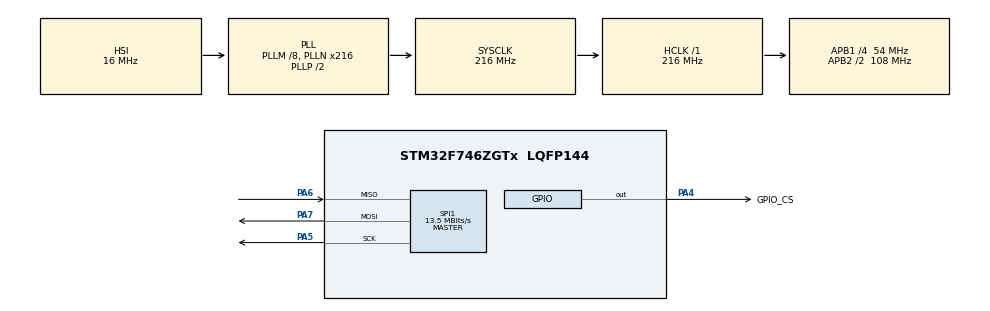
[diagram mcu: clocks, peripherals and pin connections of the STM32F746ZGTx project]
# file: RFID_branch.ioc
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Mcu.Family=STM32F7
Mcu.Name=STM32F746ZGTx
Mcu.Package=LQFP144
NVIC.PriorityGroup=NVIC_PRIORITYGROUP_4
PA4.GPIO_Label=GPIO_CS
PA4.Signal=GPIO_Output
PA5.Mode=Full_Duplex_Master
PA5.Signal=SPI1_SCK
PA6.Mode=Full_Duplex_Master
PA6.Signal=SPI1_MISO
PA7.Mode=Full_Duplex_Master
PA7.Signal=SPI1_MOSI
PH0/OSC_IN.Mode=HSE-External-Oscillator
PH0/OSC_IN.Signal=RCC_OSC_IN
PH1/OSC_OUT.Mode=HSE-External-Oscillator
PH1/OSC_OUT.Signal=RCC_OSC_OUT
ProjectManager.HeapSize=0x200
ProjectManager.StackSize=0x400
ProjectManager.TargetToolchain=STM32CubeIDE
RCC.AHBFreq_Value=216000000
RCC.APB1CLKDivider=RCC_HCLK_DIV4
RCC.APB1Freq_Value=54000000
RCC.APB1TimFreq_Value=108000000
RCC.APB2CLKDivider=RCC_HCLK_DIV2
RCC.APB2Freq_Value=108000000
RCC.APB2TimFreq_Value=216000000
RCC.CortexFreq_Value=216000000
RCC.HCLKFreq_Value=216000000
RCC.HSE_VALUE=25000000
RCC.HSI_VALUE=16000000
RCC.LSE_VALUE=32768
RCC.PLLM=8
RCC.PLLN=216
RCC.SYSCLKFreq_VALUE=216000000
RCC.SYSCLKSource=RCC_SYSCLKSOURCE_PLLCLK
RCC.USBFreq_Value=216000000
RCC.VCOOutputFreq_Value=432000000
SPI1.BaudRatePrescaler=SPI_BAUDRATEPRESCALER_8
SPI1.CalculateBaudRate=13.5 MBits/s
SPI1.DataSize=SPI_DATASIZE_8BIT
SPI1.Direction=SPI_DIRECTION_2LINES
SPI1.Mode=SPI_MODE_MASTER
SPI1.VirtualType=VM_MASTER
board=custom

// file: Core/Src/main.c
/* USER CODE BEGIN Header */
/**
  ******************************************************************************
  * @file           : main.c
  * @brief          : Main program body
  ******************************************************************************
  * @attention
  *
  * <h2><center>&copy; Copyright (c) 2021 STMicroelectronics.
  * All rights reserved.</center></h2>
  *
  * This software component is licensed by ST under BSD 3-Clause license,
  * the "License"; You may not use this file except in compliance with the
  * License. You may obtain a copy of the License at:
  *                        opensource.org/licenses/BSD-3-Clause
  *
  ******************************************************************************
  */
/* USER CODE END Header */
#include "main.h"

/* USER CODE BEGIN Includes */

#include "rfid-rc522.h"

/* USER CODE END Includes */

void SystemClock_Config(void);
static void MX_GPIO_Init(void);
static void MX_SPI1_Init(void);

int main(void)
{
  /* USER CODE BEGIN 1 */

  // TODO: set chip select high!
  HAL_GPIO_WritePin(GPIOA, GPIO_PIN_4, GPIO_PIN_RESET);

  /* Recognized card ID */
  uint8_t CardID[4];
  uint8_t type;
  char *result;
  uint8_t my_int_x;

  /* USER CODE END 1 */

  /* MCU Configuration--------------------------------------------------------*/

  /* Reset of all peripherals, Initializes the Flash interface and the Systick. */
  HAL_Init();

  /* Configure the system clock */
  SystemClock_Config();

  /* Initialize all configured peripherals */
  MX_GPIO_Init();
  MX_SPI1_Init();
  /* USER CODE BEGIN 2 */

  RFID_RC522_Init();

  /* USER CODE END 2 */

  /* Infinite loop */
  while (1)
  {

    /* USER CODE BEGIN 3 */

    int status = TM_MFRC522_Check(CardID, &type);
  	if (status == MI_OK) {
      my_int_x = my_int_x + 1;
      // LCD_UsrLog ((char *)"Found tag: ");
      // bin_to_strhex((unsigned char *)CardID, sizeof(CardID), &result);
      // LCD_UsrLog ((char *)result);
      // LCD_UsrLog ((char *)"\n");
      // LCD_UsrLog ((char *)"Type is: ");
      // bin_to_strhex((unsigned char *)&type, 1, &result);
      // LCD_UsrLog ((char *)result);
      // LCD_UsrLog ((char *)"\n");

  	} else {
        if (status == MI_TIMEOUT) {
            // LCD_UsrLog ((char *)"No tag found.\n");
        }
        if (status == MI_ERR) {
            // LCD_UsrLog ((char *)"Error.\n");
        }
    }

  }
  /* USER CODE END 3 */
}

void SystemClock_Config(void)
{
  RCC_OscInitTypeDef RCC_OscInitStruct = {0};
  RCC_ClkInitTypeDef RCC_ClkInitStruct = {0};

  /** Configure the main internal regulator output voltage
  */
  __HAL_RCC_PWR_CLK_ENABLE();
  __HAL_PWR_VOLTAGESCALING_CONFIG(PWR_REGULATOR_VOLTAGE_SCALE1);
  /** Initializes the RCC Oscillators according to the specified parameters
  * in the RCC_OscInitTypeDef structure.
  */
  RCC_OscInitStruct.OscillatorType = RCC_OSCILLATORTYPE_HSI;
  RCC_OscInitStruct.HSIState = RCC_HSI_ON;
  RCC_OscInitStruct.HSICalibrationValue = RCC_HSICALIBRATION_DEFAULT;
  RCC_OscInitStruct.PLL.PLLState = RCC_PLL_ON;
  RCC_OscInitStruct.PLL.PLLSource = RCC_PLLSOURCE_HSI;
  RCC_OscInitStruct.PLL.PLLM = 8;
  RCC_OscInitStruct.PLL.PLLN = 216;
  RCC_OscInitStruct.PLL.PLLP = RCC_PLLP_DIV2;
  RCC_OscInitStruct.PLL.PLLQ = 2;
  if (HAL_RCC_OscConfig(&RCC_OscInitStruct) != HAL_OK)
  {
    Error_Handler();
  }
  /** Activate the Over-Drive mode
  */
  if (HAL_PWREx_EnableOverDrive() != HAL_OK)
  {
    Error_Handler();
  }
  /** Initializes the CPU, AHB and APB buses clocks
  */
  RCC_ClkInitStruct.ClockType = RCC_CLOCKTYPE_HCLK|RCC_CLOCKTYPE_SYSCLK
                              |RCC_CLOCKTYPE_PCLK1|RCC_CLOCKTYPE_PCLK2;
  RCC_ClkInitStruct.SYSCLKSource = RCC_SYSCLKSOURCE_PLLCLK;
  RCC_ClkInitStruct.AHBCLKDivider = RCC_SYSCLK_DIV1;
  RCC_ClkInitStruct.APB1CLKDivider = RCC_HCLK_DIV4;
  RCC_ClkInitStruct.APB2CLKDivider = RCC_HCLK_DIV2;

  if (HAL_RCC_ClockConfig(&RCC_ClkInitStruct, FLASH_LATENCY_7) != HAL_OK)
  {
    Error_Handler();
  }
}

static void MX_SPI1_Init(void)
{

  /* SPI1 parameter configuration*/
  hspi1.Instance = SPI1;
  hspi1.Init.Mode = SPI_MODE_MASTER;
  hspi1.Init.Direction = SPI_DIRECTION_2LINES;
  hspi1.Init.DataSize = SPI_DATASIZE_8BIT;
  hspi1.Init.CLKPolarity = SPI_POLARITY_LOW;
  hspi1.Init.CLKPhase = SPI_PHASE_1EDGE;
  hspi1.Init.NSS = SPI_NSS_SOFT;
  hspi1.Init.BaudRatePrescaler = SPI_BAUDRATEPRESCALER_8;
  hspi1.Init.FirstBit = SPI_FIRSTBIT_MSB;
  hspi1.Init.TIMode = SPI_TIMODE_DISABLE;
  hspi1.Init.CRCCalculation = SPI_CRCCALCULATION_DISABLE;
  hspi1.Init.CRCPolynomial = 7;
  hspi1.Init.CRCLength = SPI_CRC_LENGTH_DATASIZE;
  hspi1.Init.NSSPMode = SPI_NSS_PULSE_ENABLE;
  if (HAL_SPI_Init(&hspi1) != HAL_OK)
  {
    Error_Handler();
  }

}

static void MX_GPIO_Init(void)
{
  GPIO_InitTypeDef GPIO_InitStruct = {0};

  /* GPIO Ports Clock Enable */
  __HAL_RCC_GPIOH_CLK_ENABLE();
  __HAL_RCC_GPIOA_CLK_ENABLE();

  /*Configure GPIO pin Output Level */
  HAL_GPIO_WritePin(GPIO_CS_GPIO_Port, GPIO_CS_Pin, GPIO_PIN_RESET);

  /*Configure GPIO pin : GPIO_CS_Pin */
  GPIO_InitStruct.Pin = GPIO_CS_Pin;
  GPIO_InitStruct.Mode = GPIO_MODE_OUTPUT_PP;
  GPIO_InitStruct.Pull = GPIO_NOPULL;
  GPIO_InitStruct.Speed = GPIO_SPEED_FREQ_LOW;
  HAL_GPIO_Init(GPIO_CS_GPIO_Port, &GPIO_InitStruct);

}

void Error_Handler(void)
{
  __disable_irq();
  while (1)
  {
  }
}

/************************ (C) COPYRIGHT STMicroelectronics *****END OF FILE****/
